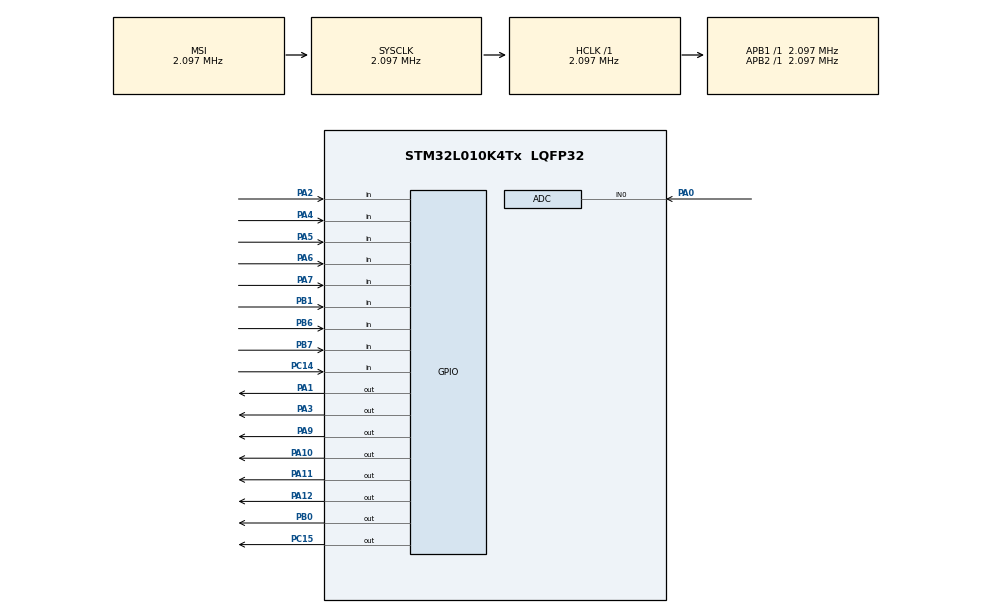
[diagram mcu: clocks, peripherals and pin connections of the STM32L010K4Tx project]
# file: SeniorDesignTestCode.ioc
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Mcu.Family=STM32L0
RCC.MSI_VALUE=2097000
PA0-CK_IN.Mode=IN0
PC14-OSC32_IN.Signal=GPIO_Input
ProjectManager.StackSize=0x400
RCC.HSI16_VALUE=16000000
PA12.Signal=GPIO_Output
ProjectManager.TargetToolchain=STM32CubeIDE
RCC.APB2TimFreq_Value=2097000
PA9.Signal=GPIO_Output
PB6.Signal=GPIO_Input
RCC.LSE_VALUE=32768
PC15-OSC32_OUT.Signal=GPIO_Output
PA1.Signal=GPIO_Output
RCC.AHBFreq_Value=2097000
PA5.Signal=GPIO_Input
RCC.HSE_VALUE=8000000
board=custom
RCC.VCOOutputFreq_Value=48000000
PA0-CK_IN.Signal=ADC_IN0
RCC.APB2Freq_Value=2097000
PB7.Signal=GPIO_Input
Mcu.Name=STM32L010K4Tx
PA2.Signal=GPIO_Input
PB3.Signal=SPI1_SCK
PA4.Signal=GPIO_Input
RCC.SYSCLKFreq_VALUE=2097000
Mcu.Package=LQFP32
PB5.Signal=SPI1_MOSI
PB1.Signal=GPIO_Input
PA6.Signal=GPIO_Input
PA11.Signal=GPIO_Output
PA10.Signal=GPIO_Output
PA15.Signal=SPI1_NSS
ProjectManager.HeapSize=0x200
RCC.HSI_VALUE=16000000
RCC.APB1TimFreq_Value=2097000
RCC.APB1Freq_Value=2097000
PB0.Signal=GPIO_Output
PB4.Signal=SPI1_MISO
PA3.Signal=GPIO_Output
PA7.Signal=GPIO_Input

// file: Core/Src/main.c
/* USER CODE BEGIN Header */
/**
  ******************************************************************************
  * @file           : main.c
  * @brief          : Main program body
  ******************************************************************************
  * @attention
  *
  * <h2><center>&copy; Copyright (c) 2021 STMicroelectronics.
  * All rights reserved.</center></h2>
  *
  * This software component is licensed by ST under BSD 3-Clause license,
  * the "License"; You may not use this file except in compliance with the
  * License. You may obtain a copy of the License at:
  *                        opensource.org/licenses/BSD-3-Clause
  *
  ******************************************************************************
  */
/* USER CODE END Header */
#include "main.h"

ADC_HandleTypeDef hadc;

void SystemClock_Config(void);
static void MX_GPIO_Init(void);
static void MX_ADC_Init(void);
/* USER CODE BEGIN PFP */
void wait (unsigned int n);
void send_lasers_on();
void send_left_click();
void send_right_click();
void send_calibration_mode();
/* USER CODE END PFP */

int main(void)
{

  /* MCU Configuration--------------------------------------------------------*/

  /* Reset of all peripherals, Initializes the Flash interface and the Systick. */
  HAL_Init();

  /* Configure the system clock */
  SystemClock_Config();

  /* Initialize all configured peripherals */
  MX_GPIO_Init();
  MX_ADC_Init();

  /* Infinite loop */
  /* USER CODE BEGIN WHILE */
  uint16_t raw;

  // Down to turn the lasers (mouse) on
  // A to left click
  // B to right click
  // 1 to enter calibration mode
  // 2 to check battery level
  // Still have plus, minus, and HOME open.
  while (1)
  {
    /* USER CODE END WHILE */

	  // Down is PA4
	  if (HAL_GPIO_ReadPin(GPIOA, GPIO_PIN_4))
	  {
		  send_lasers_on(); // Send that the lasers are about to toggle
		  HAL_GPIO_TogglePin(GPIOA, GPIO_PIN_3); // Toggle red laser
		  HAL_GPIO_TogglePin(GPIOB, GPIO_PIN_0); // Toggle IR laser
		  wait(750);
	  }

	  // A is PA6
	  if (HAL_GPIO_ReadPin(GPIOA, GPIO_PIN_6))
	  {
		  send_left_click(); // Send left click
		  wait(300);
	  }

	  // B is PA5
	  if (HAL_GPIO_ReadPin(GPIOA, GPIO_PIN_5))
	  {
		  send_right_click(); // Send right click
		  wait(300);
	  }

	  // 1 is PB7
	  if (HAL_GPIO_ReadPin(GPIOB, GPIO_PIN_7))
	  {
		  send_calibration_mode(); // Send calibration mode
		  HAL_GPIO_WritePin(GPIOA, GPIO_PIN_12, GPIO_PIN_SET); // Start with yellow 4 (going left to right)
		  wait(3000);

		  // Press B on the top left corner of the screen
		  while (HAL_GPIO_ReadPin(GPIOA, GPIO_PIN_5) == 0);
		  send_right_click(); // Send right click
		  HAL_GPIO_WritePin(GPIOA, GPIO_PIN_11, GPIO_PIN_SET); // Start with yellow 4 (going left to right)
		  wait(3000);

		  while (HAL_GPIO_ReadPin(GPIOA, GPIO_PIN_5) == 0);
		  send_right_click(); // Send right click
		  HAL_GPIO_WritePin(GPIOA, GPIO_PIN_10, GPIO_PIN_SET); // Turn on yellow 3
		  wait(3000);

		  while (HAL_GPIO_ReadPin(GPIOA, GPIO_PIN_5) == 0);
		  send_right_click(); // Send right click
		  HAL_GPIO_WritePin(GPIOA, GPIO_PIN_9, GPIO_PIN_SET); // Turn on yellow 2
		  wait(3000);

		  while (HAL_GPIO_ReadPin(GPIOA, GPIO_PIN_5) == 0);
		  send_right_click(); // Send right click

		  HAL_GPIO_WritePin(GPIOA, GPIO_PIN_12, GPIO_PIN_RESET); // Turn off yellow 4
		  HAL_GPIO_WritePin(GPIOA, GPIO_PIN_11, GPIO_PIN_RESET); // Turn off yellow 3
		  HAL_GPIO_WritePin(GPIOA, GPIO_PIN_10, GPIO_PIN_RESET); // Turn off yellow 2
		  HAL_GPIO_WritePin(GPIOA, GPIO_PIN_9, GPIO_PIN_RESET); // Turn off yellow 1
		  wait(3000);

		  // May have to more? Something about the screen size?
	  }

	  // 2 is PC14
	  if (HAL_GPIO_ReadPin(GPIOC, GPIO_PIN_14))
	  {
		  // ADC stuff
		  HAL_ADC_Start(&hadc);
		  HAL_ADC_PollForConversion(&hadc, HAL_MAX_DELAY);
		  raw = HAL_ADC_GetValue(&hadc);

		  if (raw >= 2950) // red at 2950, green anywhere below that. 2.2 V
		  {
			  HAL_GPIO_WritePin(GPIOC, GPIO_PIN_15, GPIO_PIN_SET); // Turn on the green LEDs
		  }
		  else
		  {
			  HAL_GPIO_WritePin(GPIOA, GPIO_PIN_1, GPIO_PIN_SET); // Turn on the red LEDs
		  }

		  wait(3000);
		  HAL_GPIO_WritePin(GPIOC, GPIO_PIN_15, GPIO_PIN_RESET); // Turn off the red LEDs
		  HAL_GPIO_WritePin(GPIOA, GPIO_PIN_1, GPIO_PIN_RESET); // Turn off the red LEDs

	  }

  }
}

void wait (unsigned int n)
{
	n *= 100;
	for (int i = 0; i <= n; i++);
}

void send_lasers_on()
{
	return;
}

void send_left_click()
{
	return;
}

void send_right_click()
{
	return;
}

void send_calibration_mode()
{
	return;
}

void SystemClock_Config(void)
{
  RCC_OscInitTypeDef RCC_OscInitStruct = {0};
  RCC_ClkInitTypeDef RCC_ClkInitStruct = {0};

  /** Configure the main internal regulator output voltage
  */
  __HAL_PWR_VOLTAGESCALING_CONFIG(PWR_REGULATOR_VOLTAGE_SCALE1);
  /** Initializes the RCC Oscillators according to the specified parameters
  * in the RCC_OscInitTypeDef structure.
  */
  RCC_OscInitStruct.OscillatorType = RCC_OSCILLATORTYPE_MSI;
  RCC_OscInitStruct.MSIState = RCC_MSI_ON;
  RCC_OscInitStruct.MSICalibrationValue = 0;
  RCC_OscInitStruct.MSIClockRange = RCC_MSIRANGE_5;
  RCC_OscInitStruct.PLL.PLLState = RCC_PLL_NONE;
  if (HAL_RCC_OscConfig(&RCC_OscInitStruct) != HAL_OK)
  {
    Error_Handler();
  }
  /** Initializes the CPU, AHB and APB buses clocks
  */
  RCC_ClkInitStruct.ClockType = RCC_CLOCKTYPE_HCLK|RCC_CLOCKTYPE_SYSCLK
                              |RCC_CLOCKTYPE_PCLK1|RCC_CLOCKTYPE_PCLK2;
  RCC_ClkInitStruct.SYSCLKSource = RCC_SYSCLKSOURCE_MSI;
  RCC_ClkInitStruct.AHBCLKDivider = RCC_SYSCLK_DIV1;
  RCC_ClkInitStruct.APB1CLKDivider = RCC_HCLK_DIV1;
  RCC_ClkInitStruct.APB2CLKDivider = RCC_HCLK_DIV1;

  if (HAL_RCC_ClockConfig(&RCC_ClkInitStruct, FLASH_LATENCY_0) != HAL_OK)
  {
    Error_Handler();
  }
}

static void MX_ADC_Init(void)
{

  ADC_ChannelConfTypeDef sConfig = {0};

  /** Configure the global features of the ADC (Clock, Resolution, Data Alignment and number of conversion)
  */
  hadc.Instance = ADC1;
  hadc.Init.OversamplingMode = DISABLE;
  hadc.Init.ClockPrescaler = ADC_CLOCK_SYNC_PCLK_DIV1;
  hadc.Init.Resolution = ADC_RESOLUTION_12B;
  hadc.Init.SamplingTime = ADC_SAMPLETIME_1CYCLE_5;
  hadc.Init.ScanConvMode = ADC_SCAN_DIRECTION_FORWARD;
  hadc.Init.DataAlign = ADC_DATAALIGN_RIGHT;
  hadc.Init.ContinuousConvMode = DISABLE;
  hadc.Init.DiscontinuousConvMode = DISABLE;
  hadc.Init.ExternalTrigConvEdge = ADC_EXTERNALTRIGCONVEDGE_NONE;
  hadc.Init.ExternalTrigConv = ADC_SOFTWARE_START;
  hadc.Init.DMAContinuousRequests = DISABLE;
  hadc.Init.EOCSelection = ADC_EOC_SINGLE_CONV;
  hadc.Init.Overrun = ADC_OVR_DATA_PRESERVED;
  hadc.Init.LowPowerAutoWait = DISABLE;
  hadc.Init.LowPowerFrequencyMode = ENABLE;
  hadc.Init.LowPowerAutoPowerOff = DISABLE;
  if (HAL_ADC_Init(&hadc) != HAL_OK)
  {
    Error_Handler();
  }
  /** Configure for the selected ADC regular channel to be converted.
  */
  sConfig.Channel = ADC_CHANNEL_0;
  sConfig.Rank = ADC_RANK_CHANNEL_NUMBER;
  if (HAL_ADC_ConfigChannel(&hadc, &sConfig) != HAL_OK)
  {
    Error_Handler();
  }

}

static void MX_GPIO_Init(void)
{
  GPIO_InitTypeDef GPIO_InitStruct = {0};

  /* GPIO Ports Clock Enable */
  __HAL_RCC_GPIOC_CLK_ENABLE();
  __HAL_RCC_GPIOA_CLK_ENABLE();
  __HAL_RCC_GPIOB_CLK_ENABLE();

  /*Configure GPIO pin Output Level */
  HAL_GPIO_WritePin(GPIOC, GPIO_PIN_15, GPIO_PIN_RESET);

  /*Configure GPIO pin Output Level */
  HAL_GPIO_WritePin(GPIOA, GPIO_PIN_1|GPIO_PIN_3|GPIO_PIN_9|GPIO_PIN_10
                          |GPIO_PIN_11|GPIO_PIN_12, GPIO_PIN_RESET);

  /*Configure GPIO pin Output Level */
  HAL_GPIO_WritePin(GPIOB, GPIO_PIN_0, GPIO_PIN_RESET);

  /*Configure GPIO pin : PC14 */
  GPIO_InitStruct.Pin = GPIO_PIN_14;
  GPIO_InitStruct.Mode = GPIO_MODE_INPUT;
  GPIO_InitStruct.Pull = GPIO_NOPULL;
  HAL_GPIO_Init(GPIOC, &GPIO_InitStruct);

  /*Configure GPIO pin : PC15 */
  GPIO_InitStruct.Pin = GPIO_PIN_15;
  GPIO_InitStruct.Mode = GPIO_MODE_OUTPUT_PP;
  GPIO_InitStruct.Pull = GPIO_NOPULL;
  GPIO_InitStruct.Speed = GPIO_SPEED_FREQ_LOW;
  HAL_GPIO_Init(GPIOC, &GPIO_InitStruct);

  /*Configure GPIO pins : PA1 PA3 PA9 PA10
                           PA11 PA12 */
  GPIO_InitStruct.Pin = GPIO_PIN_1|GPIO_PIN_3|GPIO_PIN_9|GPIO_PIN_10
                          |GPIO_PIN_11|GPIO_PIN_12;
  GPIO_InitStruct.Mode = GPIO_MODE_OUTPUT_PP;
  GPIO_InitStruct.Pull = GPIO_NOPULL;
  GPIO_InitStruct.Speed = GPIO_SPEED_FREQ_LOW;
  HAL_GPIO_Init(GPIOA, &GPIO_InitStruct);

  /*Configure GPIO pins : PA2 PA4 PA5 PA6
                           PA7 */
  GPIO_InitStruct.Pin = GPIO_PIN_2|GPIO_PIN_4|GPIO_PIN_5|GPIO_PIN_6
                          |GPIO_PIN_7;
  GPIO_InitStruct.Mode = GPIO_MODE_INPUT;
  GPIO_InitStruct.Pull = GPIO_NOPULL;
  HAL_GPIO_Init(GPIOA, &GPIO_InitStruct);

  /*Configure GPIO pin : PB0 */
  GPIO_InitStruct.Pin = GPIO_PIN_0;
  GPIO_InitStruct.Mode = GPIO_MODE_OUTPUT_PP;
  GPIO_InitStruct.Pull = GPIO_NOPULL;
  GPIO_InitStruct.Speed = GPIO_SPEED_FREQ_LOW;
  HAL_GPIO_Init(GPIOB, &GPIO_InitStruct);

  /*Configure GPIO pins : PB1 PB7 */
  GPIO_InitStruct.Pin = GPIO_PIN_1|GPIO_PIN_7;
  GPIO_InitStruct.Mode = GPIO_MODE_INPUT;
  GPIO_InitStruct.Pull = GPIO_NOPULL;
  HAL_GPIO_Init(GPIOB, &GPIO_InitStruct);

  /*Configure GPIO pin : PA15 */
  GPIO_InitStruct.Pin = GPIO_PIN_15;
  GPIO_InitStruct.Mode = GPIO_MODE_AF_PP;
  GPIO_InitStruct.Pull = GPIO_NOPULL;
  GPIO_InitStruct.Speed = GPIO_SPEED_FREQ_VERY_HIGH;
  GPIO_InitStruct.Alternate = GPIO_AF0_SPI1;
  HAL_GPIO_Init(GPIOA, &GPIO_InitStruct);

  /*Configure GPIO pins : PB3 PB4 PB5 */
  GPIO_InitStruct.Pin = GPIO_PIN_3|GPIO_PIN_4|GPIO_PIN_5;
  GPIO_InitStruct.Mode = GPIO_MODE_AF_PP;
  GPIO_InitStruct.Pull = GPIO_NOPULL;
  GPIO_InitStruct.Speed = GPIO_SPEED_FREQ_VERY_HIGH;
  GPIO_InitStruct.Alternate = GPIO_AF0_SPI1;
  HAL_GPIO_Init(GPIOB, &GPIO_InitStruct);

  /*Configure GPIO pin : PB6 */
  GPIO_InitStruct.Pin = GPIO_PIN_6;
  GPIO_InitStruct.Mode = GPIO_MODE_IT_RISING;
  GPIO_InitStruct.Pull = GPIO_NOPULL;
  HAL_GPIO_Init(GPIOB, &GPIO_InitStruct);

}

void Error_Handler(void)
{
  __disable_irq();
  while (1)
  {
  }
}

/************************ (C) COPYRIGHT STMicroelectronics *****END OF FILE****/
